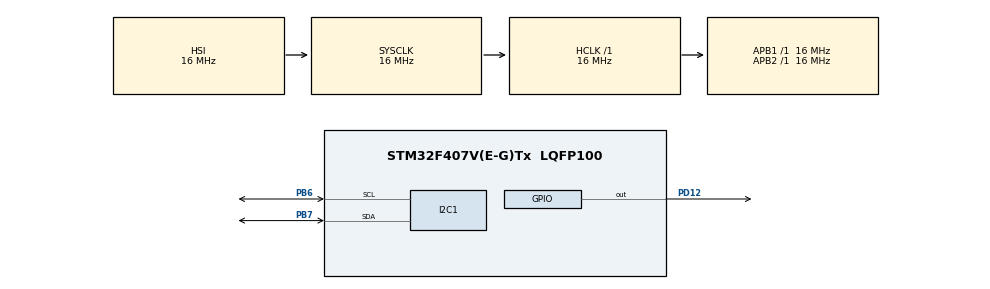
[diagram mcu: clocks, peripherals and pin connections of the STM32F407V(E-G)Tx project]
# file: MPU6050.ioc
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Mcu.Family=STM32F4
Mcu.Name=STM32F407V(E-G)Tx
Mcu.Package=LQFP100
NVIC.PriorityGroup=NVIC_PRIORITYGROUP_4
PA13.Mode=Serial_Wire
PA13.Signal=SYS_JTMS-SWDIO
PA14.Mode=Serial_Wire
PA14.Signal=SYS_JTCK-SWCLK
PB6.Mode=I2C
PB6.Signal=I2C1_SCL
PB7.Mode=I2C
PB7.Signal=I2C1_SDA
PD12.Signal=GPIO_Output
ProjectManager.HeapSize=0x200
ProjectManager.StackSize=0x400
ProjectManager.TargetToolchain=Makefile
RCC.AHBFreq_Value=16000000
RCC.APB1Freq_Value=16000000
RCC.APB2Freq_Value=16000000
RCC.CortexFreq_Value=16000000
RCC.HSE_VALUE=25000000
RCC.HSI_VALUE=16000000
RCC.LSE_VALUE=32768
RCC.SYSCLKFreq_VALUE=16000000
RCC.VCOOutputFreq_Value=192000000
board=custom

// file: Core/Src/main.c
/* USER CODE BEGIN Header */
/**
  ******************************************************************************
  * @file           : main.c
  * @brief          : Main program body
  ******************************************************************************
  * @attention
  *
  * Copyright (c) 2025 STMicroelectronics.
  * All rights reserved.
  *
  * This software is licensed under terms that can be found in the LICENSE file
  * in the root directory of this software component.
  * If no LICENSE file comes with this software, it is provided AS-IS.
  *
  ******************************************************************************
  */
/* USER CODE END Header */
#include "main.h"

/* USER CODE BEGIN PD */
#define MPU6050_ADDR 0x68<<1
#define PWR_MGMT_1  0x6B
/* USER CODE END PD */

I2C_HandleTypeDef hi2c1;

void SystemClock_Config(void);
static void MX_GPIO_Init(void);
static void MX_I2C1_Init(void);
void Power_Management_1(void);
void MPU6050_Init(void);
void _rate_cfg(void);
void GYRO_ACCEL_cfg(void);
void  MPU6050_Read_Gyro(void);

/* USER CODE BEGIN 0 */
void Power_Management_1(void){
  uint8_t data = 0x00;
  HAL_I2C_Mem_Write(&hi2c1, MPU6050_ADDR, 0x6B, 1, &data, 1, 1000);
  // data = 0xA0;
  // HAL_I2C_Mem_Write(&hi2c1, MPU6050_ADDR, 0x6B, 1, &data, 1, 1000);
}
void Sample_rate_cfg(void){
	uint8_t Data = 0;
	HAL_I2C_Mem_Write(&hi2c1, MPU6050_ADDR, 0x6B, 1, &Data, 1, 1000);

}
void GYRO_ACCEL_cfg(void){
  uint8_t data = 0x00;
  HAL_I2C_Mem_Write(&hi2c1, MPU6050_ADDR, 0x1B, 1, &data, 1, 1000); // config gyro
  HAL_I2C_Mem_Write(&hi2c1, MPU6050_ADDR, 0x1C, 1, &data, 1, 1000); // config accel
}
void MPU6050_Init(void){
  uint8_t data;
  uint8_t check;
  check = HAL_I2C_Mem_Read(&hi2c1, MPU6050_ADDR, 0x75, 1, &data,1, 1000 );
  if(data == 0x68){
    Power_Management_1();
    Sample_rate_cfg();
    GYRO_ACCEL_cfg();

  }
}
uint16_t Gyro_X_RAW;
uint16_t Gyro_Y_RAW;
uint16_t Gyro_Z_RAW;
float Gx;
float Gy;
float Gz;
uint16_t Rec_Data[6];
void MPU6050_Read_Gyro (void)
{

  HAL_I2C_Mem_Read (&hi2c1, MPU6050_ADDR, 0x43, 1, Rec_Data, 6, 1000);
  Gyro_X_RAW = (int16_t)(Rec_Data[0] << 8 | Rec_Data [1]);
  Gyro_Y_RAW = (int16_t)(Rec_Data[2] << 8 | Rec_Data [3]);
  Gyro_Z_RAW = (int16_t)(Rec_Data[4] << 8 | Rec_Data [5]);
  Gx = (float)Gyro_X_RAW/131.0;
  Gy = (float)Gyro_Y_RAW/131.0;
  Gz = (float)Gyro_Z_RAW/131.0;
}
/* USER CODE END 0 */

int main(void)
{

  /* MCU Configuration--------------------------------------------------------*/

  /* Reset of all peripherals, Initializes the Flash interface and the Systick. */
  HAL_Init();

  /* Configure the system clock */
  SystemClock_Config();

  /* Initialize all configured peripherals */
  MX_GPIO_Init();
  MX_I2C1_Init();
  MPU6050_Init();
  /* Infinite loop */
  while (1)
  {
    /* USER CODE BEGIN 3 */

   MPU6050_Read_Gyro ();
   HAL_Delay(100);

  }
  /* USER CODE END 3 */
}

void SystemClock_Config(void)
{
  RCC_OscInitTypeDef RCC_OscInitStruct = {0};
  RCC_ClkInitTypeDef RCC_ClkInitStruct = {0};

  /** Configure the main internal regulator output voltage
  */
  __HAL_RCC_PWR_CLK_ENABLE();
  __HAL_PWR_VOLTAGESCALING_CONFIG(PWR_REGULATOR_VOLTAGE_SCALE1);

  /** Initializes the RCC Oscillators according to the specified parameters
  * in the RCC_OscInitTypeDef structure.
  */
  RCC_OscInitStruct.OscillatorType = RCC_OSCILLATORTYPE_HSI;
  RCC_OscInitStruct.HSIState = RCC_HSI_ON;
  RCC_OscInitStruct.HSICalibrationValue = RCC_HSICALIBRATION_DEFAULT;
  RCC_OscInitStruct.PLL.PLLState = RCC_PLL_NONE;
  if (HAL_RCC_OscConfig(&RCC_OscInitStruct) != HAL_OK)
  {
    Error_Handler();
  }

  /** Initializes the CPU, AHB and APB buses clocks
  */
  RCC_ClkInitStruct.ClockType = RCC_CLOCKTYPE_HCLK|RCC_CLOCKTYPE_SYSCLK
                              |RCC_CLOCKTYPE_PCLK1|RCC_CLOCKTYPE_PCLK2;
  RCC_ClkInitStruct.SYSCLKSource = RCC_SYSCLKSOURCE_HSI;
  RCC_ClkInitStruct.AHBCLKDivider = RCC_SYSCLK_DIV1;
  RCC_ClkInitStruct.APB1CLKDivider = RCC_HCLK_DIV1;
  RCC_ClkInitStruct.APB2CLKDivider = RCC_HCLK_DIV1;

  if (HAL_RCC_ClockConfig(&RCC_ClkInitStruct, FLASH_LATENCY_0) != HAL_OK)
  {
    Error_Handler();
  }
}

static void MX_I2C1_Init(void)
{

  hi2c1.Instance = I2C1;
  hi2c1.Init.ClockSpeed = 100000;
  hi2c1.Init.DutyCycle = I2C_DUTYCYCLE_2;
  hi2c1.Init.OwnAddress1 = 0;
  hi2c1.Init.AddressingMode = I2C_ADDRESSINGMODE_7BIT;
  hi2c1.Init.DualAddressMode = I2C_DUALADDRESS_DISABLE;
  hi2c1.Init.OwnAddress2 = 0;
  hi2c1.Init.GeneralCallMode = I2C_GENERALCALL_DISABLE;
  hi2c1.Init.NoStretchMode = I2C_NOSTRETCH_DISABLE;
  if (HAL_I2C_Init(&hi2c1) != HAL_OK)
  {
    Error_Handler();
  }

}

static void MX_GPIO_Init(void)
{

  /* GPIO Ports Clock Enable */
  __HAL_RCC_GPIOA_CLK_ENABLE();
  __HAL_RCC_GPIOB_CLK_ENABLE();

}

void Error_Handler(void)
{
  __disable_irq();
  while (1)
  {
  }
}
